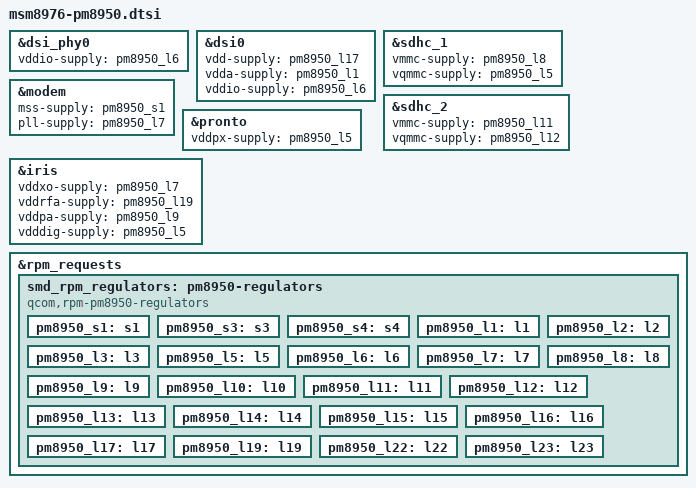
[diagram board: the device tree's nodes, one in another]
// SPDX-License-Identifier: GPL-2.0-only
// Copyright (c) 2020, The Linux Foundation. All rights reserved.

#include "msm8976.dtsi"
#include "pm8950.dtsi"

/*
&hsusb_phy {
	phy-supply = <&pm8953_l3>;
	vdda-pll-supply = <&pm8953_l7>;
	vdda-phy-dpdm-supply = <&pm8953_l13>;
};


&camss {
	vdda-supply = <&pm8953_s3>;
};

*/

&dsi_phy0 {
	vddio-supply = <&pm8950_l6>;
};

&dsi0 {
	vdd-supply = <&pm8950_l17>;
	vdda-supply = <&pm8950_l1>;
	vddio-supply = <&pm8950_l6>;
};

&sdhc_1 {
	vmmc-supply = <&pm8950_l8>;
	vqmmc-supply = <&pm8950_l5>;
};

&sdhc_2 {
	vmmc-supply = <&pm8950_l11>;
	vqmmc-supply = <&pm8950_l12>;
};

&modem {
	mss-supply = <&pm8950_s1>;
	pll-supply = <&pm8950_l7>;
};

&pronto {
	vddpx-supply = <&pm8950_l5>;
};

&iris {
	vddxo-supply = <&pm8950_l7>;
	vddrfa-supply = <&pm8950_l19>;
	vddpa-supply = <&pm8950_l9>;
	vdddig-supply = <&pm8950_l5>;
};


&rpm_requests {
	smd_rpm_regulators: pm8950-regulators {
		compatible = "qcom,rpm-pm8950-regulators";

		pm8950_s1: s1 {};
		pm8950_s3: s3 {};
		pm8950_s4: s4 {};

		pm8950_l1: l1 {};
		pm8950_l2: l2 {};
		pm8950_l3: l3 {};
		pm8950_l5: l5 {};
		pm8950_l6: l6 {};
		pm8950_l7: l7 {};
		pm8950_l8: l8 {};
		pm8950_l9: l9 {};
		pm8950_l10: l10 {};
		pm8950_l11: l11 {};
		pm8950_l12: l12 {};
		pm8950_l13: l13 {};
		pm8950_l14: l14 {};
		pm8950_l15: l15 {};
		pm8950_l16: l16 {};
		pm8950_l17: l17 {};
		pm8950_l19: l19 {};
		pm8950_l22: l22 {};
		pm8950_l23: l23 {};
	};
};
